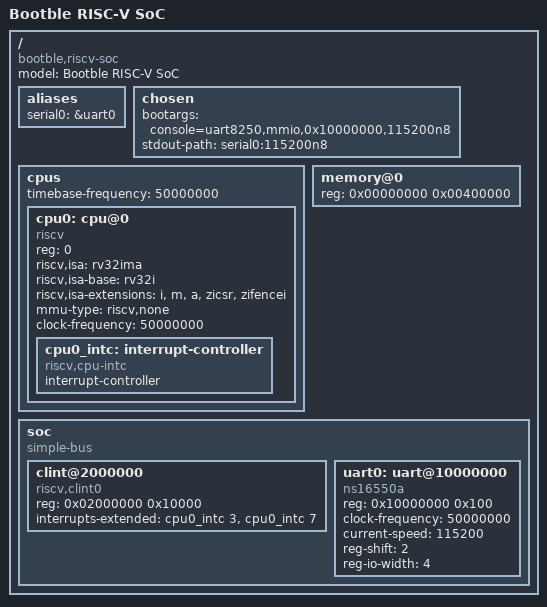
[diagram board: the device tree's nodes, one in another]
/dts-v1/;

/ {
	#address-cells = <1>;
	#size-cells = <1>;
	compatible = "bootble,riscv-soc";
	model = "Bootble RISC-V SoC";

	aliases {
		serial0 = &uart0;
	};

	chosen {
		bootargs = "console=uart8250,mmio,0x10000000,115200n8";
		stdout-path = "serial0:115200n8";
	};

	cpus {
		#address-cells = <1>;
		#size-cells = <0>;
		timebase-frequency = <50000000>;

		cpu0: cpu@0 {
			device_type = "cpu";
			reg = <0>;
			status = "okay";
			compatible = "riscv";
			riscv,isa = "rv32ima";
			riscv,isa-base = "rv32i";
			riscv,isa-extensions = "i", "m", "a", "zicsr", "zifencei";
			mmu-type = "riscv,none";
			clock-frequency = <50000000>;

			cpu0_intc: interrupt-controller {
				#interrupt-cells = <1>;
				interrupt-controller;
				compatible = "riscv,cpu-intc";
			};
		};
	};

	memory@0 {
		device_type = "memory";
		reg = <0x00000000 0x00400000>; /* 4MB */
	};

	soc {
		#address-cells = <1>;
		#size-cells = <1>;
		compatible = "simple-bus";
		ranges;

		clint@2000000 {
			compatible = "riscv,clint0";
			reg = <0x02000000 0x10000>;
			interrupts-extended = <&cpu0_intc 3 &cpu0_intc 7>;
		};

		uart0: uart@10000000 {
			compatible = "ns16550a";
			reg = <0x10000000 0x100>;
			clock-frequency = <50000000>;
			current-speed = <115200>;
			reg-shift = <2>;
			reg-io-width = <4>;
		};
	};
};
